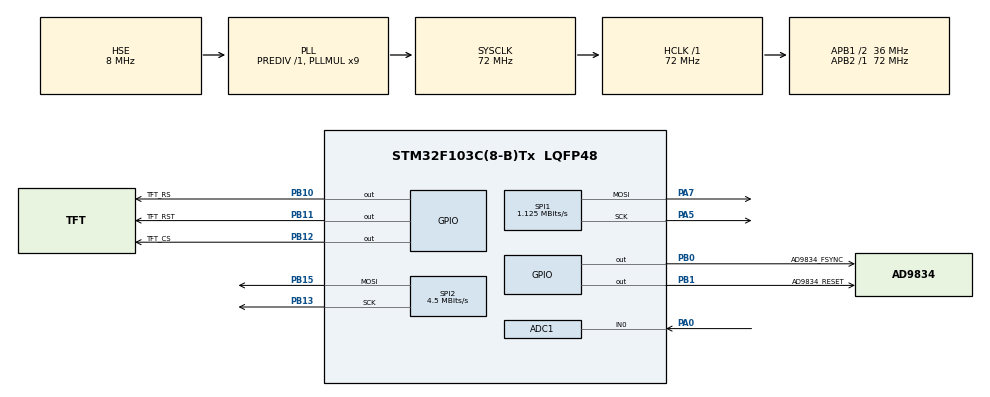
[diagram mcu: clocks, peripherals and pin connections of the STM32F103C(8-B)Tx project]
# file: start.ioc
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ADC1.Channel-0\#ChannelRegularConversion=ADC_CHANNEL_0
ADC1.NbrOfConversionFlag=1
ADC1.Rank-0\#ChannelRegularConversion=1
ADC1.SamplingTime-0\#ChannelRegularConversion=ADC_SAMPLETIME_71CYCLES_5
ADC1.master=1
Mcu.Family=STM32F1
Mcu.Name=STM32F103C(8-B)Tx
Mcu.Package=LQFP48
NVIC.PriorityGroup=NVIC_PRIORITYGROUP_4
PA0-WKUP.Signal=ADCx_IN0
PA13.Mode=Serial_Wire
PA13.Signal=SYS_JTMS-SWDIO
PA14.Mode=Serial_Wire
PA14.Signal=SYS_JTCK-SWCLK
PA5.Mode=TX_Only_Simplex_Unidirect_Master
PA5.Signal=SPI1_SCK
PA7.Mode=TX_Only_Simplex_Unidirect_Master
PA7.Signal=SPI1_MOSI
PB0.GPIO_Label=AD9834_FSYNC
PB0.GPIO_PuPd=GPIO_NOPULL
PB0.GPIO_Speed=GPIO_SPEED_FREQ_HIGH
PB0.PinState=GPIO_PIN_SET
PB0.Signal=GPIO_Output
PB1.GPIO_Label=AD9834_RESET
PB1.GPIO_Speed=GPIO_SPEED_FREQ_HIGH
PB1.PinState=GPIO_PIN_SET
PB1.Signal=GPIO_Output
PB10.GPIO_Label=TFT_RS
PB10.GPIO_Speed=GPIO_SPEED_FREQ_HIGH
PB10.PinState=GPIO_PIN_SET
PB10.Signal=GPIO_Output
PB11.GPIO_Label=TFT_RST
PB11.GPIO_Speed=GPIO_SPEED_FREQ_HIGH
PB11.PinState=GPIO_PIN_SET
PB11.Signal=GPIO_Output
PB12.GPIO_Label=TFT_CS
PB12.GPIO_Speed=GPIO_SPEED_FREQ_HIGH
PB12.PinState=GPIO_PIN_SET
PB12.Signal=GPIO_Output
PB13.Mode=TX_Only_Simplex_Unidirect_Master
PB13.Signal=SPI2_SCK
PB15.Mode=TX_Only_Simplex_Unidirect_Master
PB15.Signal=SPI2_MOSI
PD0-OSC_IN.Mode=HSE-External-Oscillator
PD0-OSC_IN.Signal=RCC_OSC_IN
PD1-OSC_OUT.Mode=HSE-External-Oscillator
PD1-OSC_OUT.Signal=RCC_OSC_OUT
ProjectManager.HeapSize=0x200
ProjectManager.StackSize=0x400
ProjectManager.TargetToolchain=STM32CubeIDE
RCC.ADCPresc=RCC_ADCPCLK2_DIV6
RCC.AHBFreq_Value=72000000
RCC.APB1CLKDivider=RCC_HCLK_DIV2
RCC.APB1Freq_Value=36000000
RCC.APB1TimFreq_Value=72000000
RCC.APB2Freq_Value=72000000
RCC.APB2TimFreq_Value=72000000
RCC.HCLKFreq_Value=72000000
RCC.PLLMUL=RCC_PLL_MUL9
RCC.PLLSourceVirtual=RCC_PLLSOURCE_HSE
RCC.SYSCLKFreq_VALUE=72000000
RCC.SYSCLKSource=RCC_SYSCLKSOURCE_PLLCLK
RCC.USBFreq_Value=72000000
SH.ADCx_IN0.0=ADC1_IN0,IN0
SPI1.BaudRatePrescaler=SPI_BAUDRATEPRESCALER_64
SPI1.CalculateBaudRate=1.125 MBits/s
SPI1.Direction=SPI_DIRECTION_2LINES
SPI1.Mode=SPI_MODE_MASTER
SPI1.VirtualType=VM_MASTER
SPI2.BaudRatePrescaler=SPI_BAUDRATEPRESCALER_8
SPI2.CalculateBaudRate=4.5 MBits/s
SPI2.Direction=SPI_DIRECTION_2LINES
SPI2.Mode=SPI_MODE_MASTER
SPI2.VirtualType=VM_MASTER
board=custom

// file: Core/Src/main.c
/* USER CODE BEGIN Header */
/**
  ******************************************************************************
  * @file           : main.c
  * @brief          : Main program body
  ******************************************************************************
  * @attention
  *
  * Copyright (c) 2026 STMicroelectronics.
  * All rights reserved.
  *
  * This software is licensed under terms that can be found in the LICENSE file
  * in the root directory of this software component.
  * If no LICENSE file comes with this software, it is provided AS-IS.
  *
  ******************************************************************************
  */
/* USER CODE END Header */
#include "main.h"
#include "adc.h"
#include "spi.h"
#include "gpio.h"

/* USER CODE BEGIN Includes */
#include "ad9834.h"
#include "st7735.h"
/* USER CODE END Includes */

void SystemClock_Config(void);

int main(void)
{

  /* MCU Configuration--------------------------------------------------------*/

  /* Reset of all peripherals, Initializes the Flash interface and the Systick. */
  HAL_Init();

  /* Configure the system clock */
  SystemClock_Config();

  /* Initialize all configured peripherals */
  MX_GPIO_Init();
  MX_ADC1_Init();
  MX_SPI1_Init();
  MX_SPI2_Init();
  /* USER CODE BEGIN 2 */
  AD9834_Init();
  ST7735_Init();
  ST7735_TestScreen();

  /* USER CODE END 2 */

  /* Infinite loop */
  while (1)
  {

  }
}

void SystemClock_Config(void)
{
  RCC_OscInitTypeDef RCC_OscInitStruct = {0};
  RCC_ClkInitTypeDef RCC_ClkInitStruct = {0};
  RCC_PeriphCLKInitTypeDef PeriphClkInit = {0};

  /** Initializes the RCC Oscillators according to the specified parameters
  * in the RCC_OscInitTypeDef structure.
  */
  RCC_OscInitStruct.OscillatorType = RCC_OSCILLATORTYPE_HSE;
  RCC_OscInitStruct.HSEState = RCC_HSE_ON;
  RCC_OscInitStruct.HSEPredivValue = RCC_HSE_PREDIV_DIV1;
  RCC_OscInitStruct.HSIState = RCC_HSI_ON;
  RCC_OscInitStruct.PLL.PLLState = RCC_PLL_ON;
  RCC_OscInitStruct.PLL.PLLSource = RCC_PLLSOURCE_HSE;
  RCC_OscInitStruct.PLL.PLLMUL = RCC_PLL_MUL9;
  if (HAL_RCC_OscConfig(&RCC_OscInitStruct) != HAL_OK)
  {
    Error_Handler();
  }

  /** Initializes the CPU, AHB and APB buses clocks
  */
  RCC_ClkInitStruct.ClockType = RCC_CLOCKTYPE_HCLK|RCC_CLOCKTYPE_SYSCLK
                              |RCC_CLOCKTYPE_PCLK1|RCC_CLOCKTYPE_PCLK2;
  RCC_ClkInitStruct.SYSCLKSource = RCC_SYSCLKSOURCE_PLLCLK;
  RCC_ClkInitStruct.AHBCLKDivider = RCC_SYSCLK_DIV1;
  RCC_ClkInitStruct.APB1CLKDivider = RCC_HCLK_DIV2;
  RCC_ClkInitStruct.APB2CLKDivider = RCC_HCLK_DIV1;

  if (HAL_RCC_ClockConfig(&RCC_ClkInitStruct, FLASH_LATENCY_2) != HAL_OK)
  {
    Error_Handler();
  }
  PeriphClkInit.PeriphClockSelection = RCC_PERIPHCLK_ADC;
  PeriphClkInit.AdcClockSelection = RCC_ADCPCLK2_DIV6;
  if (HAL_RCCEx_PeriphCLKConfig(&PeriphClkInit) != HAL_OK)
  {
    Error_Handler();
  }
}

void Error_Handler(void)
{
  __disable_irq();
  while (1)
  {
  }
}
